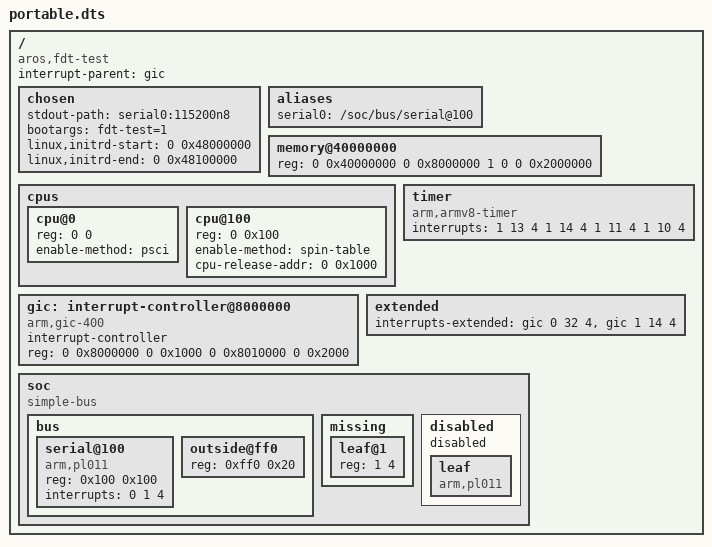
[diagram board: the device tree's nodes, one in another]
// SPDX-License-Identifier: MIT
// Copyright (c) 2026 John Knipper
/dts-v1/;
/ {
    compatible = "aros,fdt-test";
    #address-cells = <2>; #size-cells = <2>;
    interrupt-parent = <&gic>;
    chosen { stdout-path = "serial0:115200n8"; bootargs = "fdt-test=1";
        linux,initrd-start = <0 0x48000000>; linux,initrd-end = <0 0x48100000>; };
    aliases { serial0 = "/soc/bus/serial@100"; };
    memory@40000000 { device_type = "memory"; reg = <0 0x40000000 0 0x8000000 1 0 0 0x2000000>; };
    cpus { #address-cells = <2>; #size-cells = <0>;
        cpu@0 { device_type = "cpu"; reg = <0 0>; enable-method = "psci"; };
        cpu@100 { device_type = "cpu"; reg = <0 0x100>; enable-method = "spin-table"; cpu-release-addr = <0 0x1000>; };
    };
    gic: interrupt-controller@8000000 { compatible = "arm,gic-400";
        #interrupt-cells = <3>; interrupt-controller;
        reg = <0 0x8000000 0 0x1000 0 0x8010000 0 0x2000>; };
    timer { compatible = "arm,armv8-timer"; interrupts = <1 13 4 1 14 4 1 11 4 1 10 4>; };
    extended { interrupts-extended = <&gic 0 32 4 &gic 1 14 4>; };
    soc { compatible = "simple-bus"; #address-cells = <1>; #size-cells = <1>;
        ranges = <0x1000 0 0x20000000 0x10000>;
        bus { #address-cells = <1>; #size-cells = <1>; ranges = <0 0x2000 0x1000>;
            serial@100 { compatible = "arm,pl011"; reg = <0x100 0x100>; interrupts = <0 1 4>; };
            outside@ff0 { reg = <0xff0 0x20>; };
        };
        missing { #address-cells = <1>; #size-cells = <1>; leaf@1 { reg = <1 4>; }; };
        disabled { status = "disabled"; leaf { compatible = "arm,pl011"; }; };
    };
};
